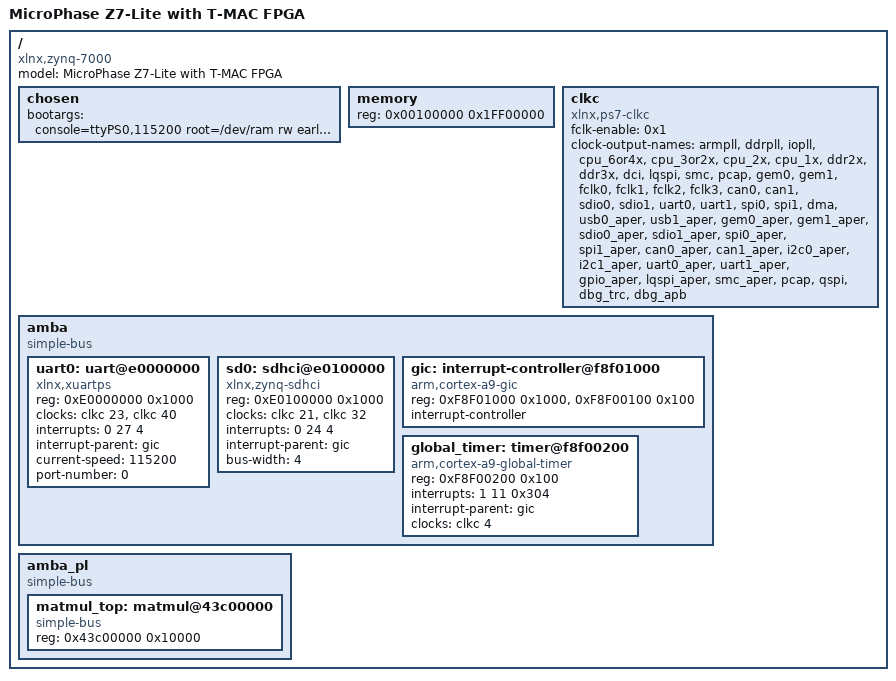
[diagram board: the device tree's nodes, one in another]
// Device Tree for MicroPhase Z7-Lite + hp_fsm_top accelerator
// Reference: Xilinx Zynq-7000 device tree conventions
// Build: dtc -I dts -O dtb -o devicetree.dtb zynq-microzed.dts

/dts-v1/;
/ {
    #address-cells = <1>;
    #size-cells = <1>;
    model = "MicroPhase Z7-Lite with T-MAC FPGA";
    compatible = "xlnx,zynq-7000";

    chosen {
        bootargs = "console=ttyPS0,115200 root=/dev/ram rw earlyprintk";
    };

    memory {
        device_type = "memory";
        reg = <0x00100000 0x1FF00000>;  /* 512MB minus 1MB hole */
    };

    /* PS7 clocks */
    clkc: clkc {
        #clock-cells = <1>;
        compatible = "xlnx,ps7-clkc";
        fclk-enable = <0x1>;  /* enable FCLK_CLK0 */
        clock-output-names = "armpll", "ddrpll", "iopll",
            "cpu_6or4x", "cpu_3or2x", "cpu_2x", "cpu_1x",
            "ddr2x", "ddr3x", "dci",
            "lqspi", "smc", "pcap", "gem0", "gem1",
            "fclk0", "fclk1", "fclk2", "fclk3",
            "can0", "can1", "sdio0", "sdio1",
            "uart0", "uart1", "spi0", "spi1",
            "dma", "usb0_aper", "usb1_aper",
            "gem0_aper", "gem1_aper",
            "sdio0_aper", "sdio1_aper",
            "spi0_aper", "spi1_aper",
            "can0_aper", "can1_aper",
            "i2c0_aper", "i2c1_aper",
            "uart0_aper", "uart1_aper",
            "gpio_aper", "lqspi_aper",
            "smc_aper", "pcap",
            "qspi", "dbg_trc", "dbg_apb";
    };

    /* PS7 peripherals */
    amba: amba {
        #address-cells = <1>;
        #size-cells = <1>;
        compatible = "simple-bus";
        ranges;

        uart0: uart@e0000000 {
            compatible = "xlnx,xuartps";
            reg = <0xE0000000 0x1000>;
            clocks = <&clkc 23>, <&clkc 40>;
            clock-names = "uart_clk", "pclk";
            interrupts = <0 27 4>;
            interrupt-parent = <&gic>;
            current-speed = <115200>;
            device_type = "serial";
            port-number = <0>;
            status = "okay";
        };

        sd0: sdhci@e0100000 {
            compatible = "xlnx,zynq-sdhci";
            reg = <0xE0100000 0x1000>;
            clocks = <&clkc 21>, <&clkc 32>;
            clock-names = "clk_xin", "clk_ahb";
            interrupts = <0 24 4>;
            interrupt-parent = <&gic>;
            bus-width = <4>;
            status = "okay";
        };

        gic: interrupt-controller@f8f01000 {
            compatible = "arm,cortex-a9-gic";
            #interrupt-cells = <3>;
            reg = <0xF8F01000 0x1000>,
                  <0xF8F00100 0x100>;
            interrupt-controller;
        };

        global_timer: timer@f8f00200 {
            compatible = "arm,cortex-a9-global-timer";
            reg = <0xF8F00200 0x100>;
            interrupts = <1 11 0x304>;
            interrupt-parent = <&gic>;
            clocks = <&clkc 4>;
        };
    };

    /* PL (FPGA) peripherals */
    amba_pl: amba_pl {
        #address-cells = <1>;
        #size-cells = <1>;
        compatible = "simple-bus";
        ranges;

        matmul_top: matmul@43c00000 {
            compatible = "simple-bus";
            reg = <0x43c00000 0x10000>;
            status = "okay";
        };
    };
};
